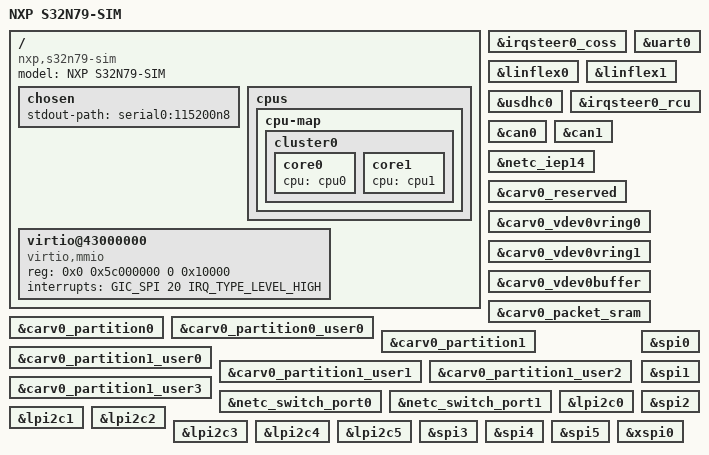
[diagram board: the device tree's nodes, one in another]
// SPDX-License-Identifier: (GPL-2.0+ OR BSD-3-Clause)
/*
 * Copyright 2024-2025 NXP
 */

/dts-v1/;
#include "s32n79-simulator.dtsi"
#include "dt-bindings/memory/s32n7-carv.h"

/ {
	model = "NXP S32N79-SIM";
	compatible = "nxp,s32n79-sim", "nxp,s32n79";

	chosen {
		stdout-path = "serial0:115200n8";
	};

	cpus {
		cpu-map {
			cluster0 {
				core0 {
					cpu = <&cpu0>;
				};

				core1 {
					cpu = <&cpu1>;
				};
			};
		};
	};

	virtio@43000000 {
		compatible = "virtio,mmio";
		reg = <0x0 0x5c000000 0 0x10000>;
		interrupts = <GIC_SPI 20 IRQ_TYPE_LEVEL_HIGH>;
	};
};

&irqsteer0_coss {
	status = "okay";
};

&uart0 {
	status = "okay";
};

&linflex0 {
	status = "okay";
};

&linflex1 {
	status = "okay";
};

&usdhc0 {
	status = "okay";
};

&irqsteer0_rcu {
	status = "okay";
};

&can0 {
	status = "okay";
};

&can1 {
	status = "okay";
};

&netc_iep14 {
	status = "okay";
};

&carv0_reserved {
	status = "okay";
};

&carv0_vdev0vring0 {
	status = "okay";
};

&carv0_vdev0vring1 {
	status = "okay";
};

&carv0_vdev0buffer {
	status = "okay";
};

&carv0_packet_sram {
	status = "okay";
};

&carv0_partition0 {
	status = "okay";
};

&carv0_partition0_user0 {
	status = "okay";
};

&carv0_partition1 {
	status = "okay";
};

&carv0_partition1_user0 {
	status = "okay";
};

&carv0_partition1_user1 {
	status = "okay";
};

&carv0_partition1_user2 {
	status = "okay";
};

&carv0_partition1_user3 {
	status = "okay";
};

&netc_switch_port0 {
	status = "okay";
};

&netc_switch_port1 {
	status = "okay";
};

&lpi2c0 {
	status = "okay";
};

&lpi2c1 {
	status = "okay";
};

&lpi2c2 {
	status = "okay";
};

&lpi2c3 {
	status = "okay";
};

&lpi2c4 {
	status = "okay";
};

&lpi2c5 {
	status = "okay";
};

&spi0 {
	status = "okay";
};

&spi1 {
	status = "okay";
};

&spi2 {
	status = "okay";
};

&spi3 {
	status = "okay";
};

&spi4 {
	status = "okay";
};

&spi5 {
	status = "okay";
};

&xspi0 {
	status = "okay";
};
